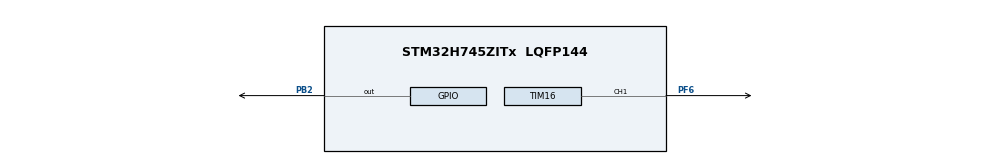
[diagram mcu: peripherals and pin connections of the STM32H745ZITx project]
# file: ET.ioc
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CortexM4.IPs=BDMA,CORTEX_M4\:I,DEBUG,DMA,FATFS_M4\:I,FREERTOS_M4\:I,GPIO,IWDG2\:I,MDMA,NVIC2\:I,OPENAMP_M4\:I,PDM2PCM_M4\:I,PWR,RCC,RESMGR_UTILITY,SYS_M4\:I,USB_DEVICE_M4\:I,USB_HOST_M4\:I,VREFBUF,WWDG2\:I
CortexM7.IPs=BDMA\:I,CORTEX_M7\:I,DEBUG\:I,DMA\:I,FATFS_M7\:I,FREERTOS_M7\:I,GPIO\:I,IWDG1\:I,MDMA\:I,NVIC1\:I,OPENAMP_M7\:I,PDM2PCM_M7\:I,PWR\:I,RCC\:I,RESMGR_UTILITY\:I,SYS\:I,USB_DEVICE_M7\:I,USB_HOST_M7\:I,VREFBUF\:I,WWDG1\:I,TIM16\:I
Mcu.Family=STM32H7
Mcu.Name=STM32H745ZITx
Mcu.Package=LQFP144
NVIC1.PriorityGroup=NVIC_PRIORITYGROUP_4
NVIC1.TIM16_IRQn=true\:0\:0\:false\:false\:true\:true\:true\:true
NVIC2.PriorityGroup=NVIC_PRIORITYGROUP_4
PB2.PinAttribute=Free
PB2.Signal=GPIO_Output
PF6.PinAttribute=CortexM7
PF6.Signal=S_TIM16_CH1
ProjectManager.HeapSize=M4-0x200,M7-0x200
ProjectManager.StackSize=M4-0x400,M7-0x400
ProjectManager.TargetToolchain=STM32CubeIDE
RCC.ADCFreq_Value=129000000
RCC.APB1Freq_Value=64000000
RCC.APB2Freq_Value=64000000
RCC.APB3Freq_Value=64000000
RCC.APB4Freq_Value=64000000
RCC.CortexFreq_Value=64000000
RCC.HCLKFreq_Value=64000000
RCC.SYSCLKFreq_VALUE=64000000
RCC.USBFreq_Value=129000000
SH.S_TIM16_CH1.0=TIM16_CH1,PWM Generation1 CH1
TIM16.AutoReloadPreload=TIM_AUTORELOAD_PRELOAD_ENABLE
TIM16.Channel=TIM_CHANNEL_1
TIM16.Period=20000-1
TIM16.Prescaler=10000-1
TIM16.Pulse=10000
VP_TIM16_VS_ClockSourceINT.Mode=Enable_Timer
board=custom

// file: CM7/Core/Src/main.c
/* USER CODE BEGIN Header */
/**
  ******************************************************************************
  * @file           : main.c
  * @brief          : Main program body
  ******************************************************************************
  * @attention
  *
  * Copyright (c) 2023 STMicroelectronics.
  * All rights reserved.
  *
  * This software is licensed under terms that can be found in the LICENSE file
  * in the root directory of this software component.
  * If no LICENSE file comes with this software, it is provided AS-IS.
  *
  ******************************************************************************
  */
/* USER CODE END Header */
#include "main.h"

/* USER CODE BEGIN PD */

#ifndef HSEM_ID_0
#define HSEM_ID_0 (0U) /* HW semaphore 0*/
#endif

/* USER CODE END PD */

TIM_HandleTypeDef htim16;

void SystemClock_Config(void);
static void MPU_Config(void);
static void MX_GPIO_Init(void);
static void MX_TIM16_Init(void);

int main(void)
{
  /* USER CODE BEGIN 1 */
//	configureOutputPin();
  /* USER CODE END 1 */
/* USER CODE BEGIN Boot_Mode_Sequence_0 */
  int32_t timeout;
/* USER CODE END Boot_Mode_Sequence_0 */

  /* MPU Configuration--------------------------------------------------------*/
  MPU_Config();

/* USER CODE BEGIN Boot_Mode_Sequence_1 */
  /* Wait until CPU2 boots and enters in stop mode or timeout*/
//  timeout = 0xFFFF;
//  while((__HAL_RCC_GET_FLAG(RCC_FLAG_D2CKRDY) != RESET) && (timeout-- > 0));
//  if ( timeout < 0 )
//  {
//  Error_Handler();
//  }
/* USER CODE END Boot_Mode_Sequence_1 */
  /* MCU Configuration--------------------------------------------------------*/

  /* Reset of all peripherals, Initializes the Flash interface and the Systick. */
  HAL_Init();

  /* USER CODE BEGIN Init */
  __HAL_RCC_GPIOB_CLK_ENABLE();
  __HAL_RCC_GPIOE_CLK_ENABLE();

  GPIO_InitTypeDef GPIO_InitStruct = {0};
  GPIO_InitStruct.Pin = GPIO_PIN_2;
  GPIO_InitStruct.Mode = GPIO_MODE_OUTPUT_PP;
  GPIO_InitStruct.Pull = GPIO_NOPULL;
  HAL_GPIO_Init(GPIOB, &GPIO_InitStruct);

  GPIO_InitTypeDef GPIOE_InitStruct = {0};
  GPIOE_InitStruct.Pin = GPIO_PIN_1;
  GPIOE_InitStruct.Mode = GPIO_MODE_OUTPUT_PP;
  GPIOE_InitStruct.Pull = GPIO_NOPULL;
  HAL_GPIO_Init(GPIOE, &GPIOE_InitStruct);
  /* USER CODE END Init */

  /* Configure the system clock */
  SystemClock_Config();
/* USER CODE BEGIN Boot_Mode_Sequence_2 */
/* When system initialization is finished, Cortex-M7 will release Cortex-M4 by means of
HSEM notification */
/*HW semaphore Clock enable*/
//__HAL_RCC_HSEM_CLK_ENABLE();
///*Take HSEM */
//HAL_HSEM_FastTake(HSEM_ID_0);
///*Release HSEM in order to notify the CPU2(CM4)*/
//HAL_HSEM_Release(HSEM_ID_0,0);
///* wait until CPU2 wakes up from stop mode */
//timeout = 0xFFFF;
//while((__HAL_RCC_GET_FLAG(RCC_FLAG_D2CKRDY) == RESET) && (timeout-- > 0));
//if ( timeout < 0 )
//{
//Error_Handler();
//}
/* USER CODE END Boot_Mode_Sequence_2 */

  /* Initialize all configured peripherals */
  MX_GPIO_Init();
  MX_TIM16_Init();

  /* Infinite loop */
  while (1)
  {

    /* USER CODE BEGIN 3 */
	  HAL_GPIO_WritePin(GPIOB, GPIO_PIN_2, SET);
	  HAL_Delay(1000);
	  HAL_GPIO_WritePin(GPIOB, GPIO_PIN_2, RESET);
	  HAL_Delay(1000);
  }
  /* USER CODE END 3 */
}

void SystemClock_Config(void)
{
  RCC_OscInitTypeDef RCC_OscInitStruct = {0};
  RCC_ClkInitTypeDef RCC_ClkInitStruct = {0};

  /** Supply configuration update enable
  */
  HAL_PWREx_ConfigSupply(PWR_DIRECT_SMPS_SUPPLY);

  /** Configure the main internal regulator output voltage
  */
  __HAL_PWR_VOLTAGESCALING_CONFIG(PWR_REGULATOR_VOLTAGE_SCALE3);

  while(!__HAL_PWR_GET_FLAG(PWR_FLAG_VOSRDY)) {}

  /** Initializes the RCC Oscillators according to the specified parameters
  * in the RCC_OscInitTypeDef structure.
  */
  RCC_OscInitStruct.OscillatorType = RCC_OSCILLATORTYPE_HSI;
  RCC_OscInitStruct.HSIState = RCC_HSI_DIV1;
  RCC_OscInitStruct.HSICalibrationValue = RCC_HSICALIBRATION_DEFAULT;
  RCC_OscInitStruct.PLL.PLLState = RCC_PLL_NONE;
  if (HAL_RCC_OscConfig(&RCC_OscInitStruct) != HAL_OK)
  {
    Error_Handler();
  }

  /** Initializes the CPU, AHB and APB buses clocks
  */
  RCC_ClkInitStruct.ClockType = RCC_CLOCKTYPE_HCLK|RCC_CLOCKTYPE_SYSCLK
                              |RCC_CLOCKTYPE_PCLK1|RCC_CLOCKTYPE_PCLK2
                              |RCC_CLOCKTYPE_D3PCLK1|RCC_CLOCKTYPE_D1PCLK1;
  RCC_ClkInitStruct.SYSCLKSource = RCC_SYSCLKSOURCE_HSI;
  RCC_ClkInitStruct.SYSCLKDivider = RCC_SYSCLK_DIV1;
  RCC_ClkInitStruct.AHBCLKDivider = RCC_HCLK_DIV1;
  RCC_ClkInitStruct.APB3CLKDivider = RCC_APB3_DIV1;
  RCC_ClkInitStruct.APB1CLKDivider = RCC_APB1_DIV1;
  RCC_ClkInitStruct.APB2CLKDivider = RCC_APB2_DIV1;
  RCC_ClkInitStruct.APB4CLKDivider = RCC_APB4_DIV1;

  if (HAL_RCC_ClockConfig(&RCC_ClkInitStruct, FLASH_LATENCY_1) != HAL_OK)
  {
    Error_Handler();
  }
}

static void MX_TIM16_Init(void)
{

  TIM_OC_InitTypeDef sConfigOC = {0};
  TIM_BreakDeadTimeConfigTypeDef sBreakDeadTimeConfig = {0};

  htim16.Instance = TIM16;
  htim16.Init.Prescaler = 10000-1;
  htim16.Init.CounterMode = TIM_COUNTERMODE_UP;
  htim16.Init.Period = 20000-1;
  htim16.Init.ClockDivision = TIM_CLOCKDIVISION_DIV1;
  htim16.Init.RepetitionCounter = 0;
  htim16.Init.AutoReloadPreload = TIM_AUTORELOAD_PRELOAD_ENABLE;
  if (HAL_TIM_Base_Init(&htim16) != HAL_OK)
  {
    Error_Handler();
  }
  if (HAL_TIM_PWM_Init(&htim16) != HAL_OK)
  {
    Error_Handler();
  }
  sConfigOC.OCMode = TIM_OCMODE_PWM1;
  sConfigOC.Pulse = 10000;
  sConfigOC.OCPolarity = TIM_OCPOLARITY_HIGH;
  sConfigOC.OCNPolarity = TIM_OCNPOLARITY_HIGH;
  sConfigOC.OCFastMode = TIM_OCFAST_DISABLE;
  sConfigOC.OCIdleState = TIM_OCIDLESTATE_RESET;
  sConfigOC.OCNIdleState = TIM_OCNIDLESTATE_RESET;
  if (HAL_TIM_PWM_ConfigChannel(&htim16, &sConfigOC, TIM_CHANNEL_1) != HAL_OK)
  {
    Error_Handler();
  }
  sBreakDeadTimeConfig.OffStateRunMode = TIM_OSSR_DISABLE;
  sBreakDeadTimeConfig.OffStateIDLEMode = TIM_OSSI_DISABLE;
  sBreakDeadTimeConfig.LockLevel = TIM_LOCKLEVEL_OFF;
  sBreakDeadTimeConfig.DeadTime = 0;
  sBreakDeadTimeConfig.BreakState = TIM_BREAK_DISABLE;
  sBreakDeadTimeConfig.BreakPolarity = TIM_BREAKPOLARITY_HIGH;
  sBreakDeadTimeConfig.BreakFilter = 0;
  sBreakDeadTimeConfig.AutomaticOutput = TIM_AUTOMATICOUTPUT_DISABLE;
  if (HAL_TIMEx_ConfigBreakDeadTime(&htim16, &sBreakDeadTimeConfig) != HAL_OK)
  {
    Error_Handler();
  }
  HAL_TIM_MspPostInit(&htim16);

}

static void MX_GPIO_Init(void)
{

  /* GPIO Ports Clock Enable */
  __HAL_RCC_GPIOF_CLK_ENABLE();

}

/* USER CODE BEGIN 4 */
void configureOutputPin(void) {
    GPIO_InitTypeDef GPIO_InitStruct = {0};

    __HAL_RCC_GPIOB_CLK_ENABLE();

    GPIO_InitStruct.Pin = GPIO_PIN_2;
    GPIO_InitStruct.Mode = GPIO_MODE_OUTPUT_PP;
    GPIO_InitStruct.Pull = GPIO_NOPULL;
    HAL_GPIO_Init(GPIOB, &GPIO_InitStruct);
}
/* USER CODE END 4 */

/* MPU Configuration */

void MPU_Config(void)
{
  MPU_Region_InitTypeDef MPU_InitStruct = {0};

  /* Disables the MPU */
  HAL_MPU_Disable();

  /** Initializes and configures the Region and the memory to be protected
  */
  MPU_InitStruct.Enable = MPU_REGION_ENABLE;
  MPU_InitStruct.Number = MPU_REGION_NUMBER0;
  MPU_InitStruct.BaseAddress = 0x0;
  MPU_InitStruct.Size = MPU_REGION_SIZE_4GB;
  MPU_InitStruct.SubRegionDisable = 0x87;
  MPU_InitStruct.TypeExtField = MPU_TEX_LEVEL0;
  MPU_InitStruct.AccessPermission = MPU_REGION_NO_ACCESS;
  MPU_InitStruct.DisableExec = MPU_INSTRUCTION_ACCESS_DISABLE;
  MPU_InitStruct.IsShareable = MPU_ACCESS_SHAREABLE;
  MPU_InitStruct.IsCacheable = MPU_ACCESS_NOT_CACHEABLE;
  MPU_InitStruct.IsBufferable = MPU_ACCESS_NOT_BUFFERABLE;

  HAL_MPU_ConfigRegion(&MPU_InitStruct);
  /* Enables the MPU */
  HAL_MPU_Enable(MPU_PRIVILEGED_DEFAULT);

}

void Error_Handler(void)
{
  __disable_irq();
  while (1)
  {
  }
}
